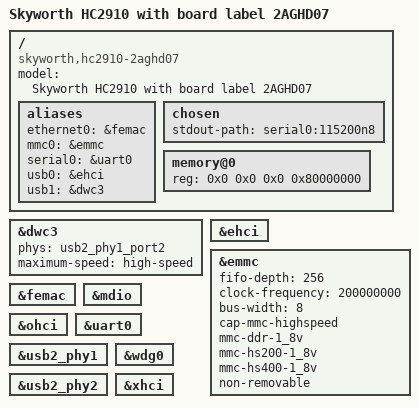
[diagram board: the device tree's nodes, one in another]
// SPDX-License-Identifier: GPL-2.0
/*
 * DTS File for Skyworth HC2910 with board label 2AGHD07 set-top box.
 *
 * Released under the GPLv2 only.
 */

/dts-v1/;

#include "hi3798mv200.dtsi"

/ {
	// Usually known as Hubei Guangdian HC2910
	model = "Skyworth HC2910 with board label 2AGHD07";
	compatible = "skyworth,hc2910-2aghd07", "hisilicon,hi3798mv200";

	aliases {
		ethernet0 = &femac;
		mmc0 = &emmc; /* eMMC */
		serial0 = &uart0;
		usb0 = &ehci;
		usb1 = &dwc3;
	};

	chosen {
		stdout-path = "serial0:115200n8";
	};

	memory@0 {
		device_type = "memory";
		reg = <0x0 0x0 0x0 0x80000000>;
	};
};

&dwc3 {
	// remove combphy since the board didn't get USB3 signal lines attached
	phys = <&usb2_phy1_port2>;
	phy-names = "inno";
	maximum-speed = "high-speed";
};

&ehci {
	status = "okay";
};

&emmc {
	fifo-depth = <256>;
	clock-frequency = <200000000>;
	bus-width = <8>;
	cap-mmc-highspeed;
	mmc-ddr-1_8v;
	mmc-hs200-1_8v;
	mmc-hs400-1_8v;
	non-removable;
	status = "okay";
};

&femac {
	status = "okay";
};

&mdio {
	status = "okay";
};

&ohci {
	status = "okay";
};

&uart0 {
	status = "okay";
};

&usb2_phy1 {
	status = "okay";
};

&usb2_phy2 {
	status = "okay";
};

&wdg0 {
	status = "okay";
};

&xhci {
	status = "okay";
};
